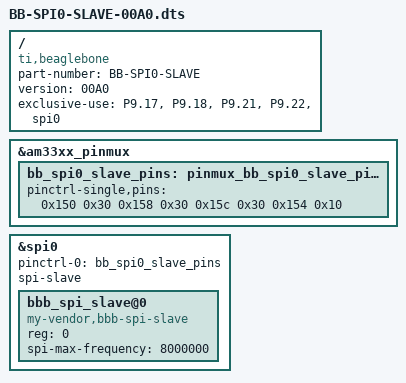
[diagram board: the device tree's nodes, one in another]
/dts-v1/;
/plugin/;

/ {
    compatible = "ti,beaglebone", "ti,beaglebone-black";

    /* identification */
    part-number = "BB-SPI0-SLAVE";
    version = "00A0";

    /* state the resources this cape uses */
    exclusive-use =
        "P9.17", /* spi0_cs0 */
        "P9.18", /* spi0_d1 */
        "P9.21", /* spi0_d0 */
        "P9.22", /* spi0_sclk */
        "spi0";

    fragment@0 {
        target = <&am33xx_pinmux>;
        __overlay__ {
            bb_spi0_slave_pins: pinmux_bb_spi0_slave_pins {
                pinctrl-single,pins = <
                    /* In slave mode, SCLK, MOSI, and CS are inputs */
                    0x150 0x30  /* P9_22: spi0_sclk, INPUT_PULLUP | MODE0 */
                    0x158 0x30  /* P9_18: spi0_d1 (MOSI), INPUT_PULLUP | MODE0 */
                    0x15c 0x30  /* P9_17: spi0_cs0, INPUT_PULLUP | MODE0 */
                    /* In slave mode, MISO is an output */
                    0x154 0x10  /* P9_21: spi0_d0 (MISO), OUTPUT_PULLUP | MODE0 */
                >;
            };
        };
    };

    fragment@1 {
        target = <&spi0>;
        __overlay__ {
            #address-cells = <1>;
            #size-cells = <0>;
            status = "okay";
            pinctrl-names = "default";
            pinctrl-0 = <&bb_spi0_slave_pins>;

            /* This is the key property to enable slave mode */
            spi-slave;

            /* Define our custom slave device node */
            bbb_spi_slave@0 {
                compatible = "my-vendor,bbb-spi-slave";
                reg = <0>; /* Chip select 0 */
                spi-max-frequency = <8000000>;
            };
        };
    };
};
